# haltium_sysctrl register map
Vendor: Nordic Semiconductor; Series: nRFHaltium; File version: 1
Registers are 32-bit, read-write, reset 0x0 unless marked. A register's access mark holds for its fields unless they carry their own. Offsets are from the block's base; [hi:lo] are bit positions; lines under a group give offsets from that group; {n}, {i} and the like mark numbered series.

## L2CACHEDATA_S — CACHEDATA
Base 0x0E000000
{0x0+0x40*i} SET[{i}] (i=0..255) group — Unspecified
  {0x0+0x20*j} WAY[{j}] (j=0..1) group — Unspecified
    {0x0+8k} DU[{k}] (k=0..3) group — Unspecified
      {0x0+4l} DATA[{l}] (l=0..1) — Description collection: Cache data bits for DATA[q] in DU[p] (DataUnit) of SET[n], WAY[o].
        [31:0] Data

## L2CACHEINFO_S — CACHEINFO
Base 0x0E008000
{0x0+8i} SET[{i}] (i=0..255) group — Unspecified
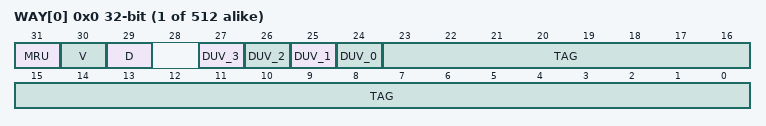
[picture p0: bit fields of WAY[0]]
  {0x0+4j} WAY[{j}] (j=0..1) — Description collection: Cache information for SET[n], WAY[o].
    [31] MRU ro — Most recently used way.
      0=Way0 was most recently used; 1=Way1 was most recently used
    [30] V ro — Line valid bit.
      0=Invalid cache line; 1=Valid cache line
    [29] D ro — Line dirty bit.
      0=Clean cache line; 1=Dirty cache line
    [n+24] DUV_{n} (n=0..3) — Data unit valid info.
      0=Invalid data unit; 1=Valid data unit
    [23:0] TAG — Cache tag.

## GLOBAL_GGENERIC59_NS — GENERIC 0
Base 0xBF001000
Same registers: GLOBAL_GGENERIC55_NS 0x4F8D3000, GLOBAL_GGENERIC56_NS 0x4F8D4000, GLOBAL_GGENERIC57_NS 0x4F8D5000, GLOBAL_GGENERIC58_NS 0x4F8D6000, GGENERIC2_S 0x5F085000, GGENERIC3_S 0x5F096000, GGENERIC6_S 0x5F8CF000, GLOBAL_GGENERIC55_S 0x5F8D3000, GLOBAL_GGENERIC56_S 0x5F8D4000, GLOBAL_GGENERIC57_S 0x5F8D5000, GLOBAL_GGENERIC58_S 0x5F8D6000, GGENERIC7_S 0x5F90E000, GGENERIC8_S 0x5F90F000, GGENERIC9_S 0x5F93C000, GGENERIC12_S 0x5F93F000, GGENERIC13_S 0x5F942000, GGENERIC14_S 0x5F944000, GGENERIC15_S 0x5F945000, GGENERIC16_S 0x5F946000, GGENERIC17_S 0x5F950000, GGENERIC18_S 0x5F952000, GGENERIC19_S 0x5F953000, GGENERIC20_S 0x5F955000, GGENERIC21_S 0x5F956000, GGENERIC22_S 0x5F957000, GGENERIC23_S 0x5F960000, GGENERIC29_S 0x5F967000, GGENERIC30_S 0x5F968000, GGENERIC32_S 0x5F96B000, GGENERIC36_S 0x5F974000, GGENERIC37_S 0x5F975000, GGENERIC38_S 0x5F976000, GGENERIC39_S 0x5F977000, GGENERIC40_S 0x5F978000, GGENERIC41_S 0x5F979000, GGENERIC42_S 0x5F97A000, GGENERIC43_S 0x5F98E000, GGENERIC44_S 0x5F98F000, GGENERIC45_S 0x5F99E000, GGENERIC46_S 0x5F99F000, GGENERIC47_S 0x5F9AE000, GGENERIC48_S 0x5F9AF000, GGENERIC49_S 0x5F9BE000, GGENERIC50_S 0x5F9BF000, GGENERIC51_S 0x5F9CE000, GGENERIC52_S 0x5F9CF000, GGENERIC53_S 0x5F9DE000, GGENERIC54_S 0x5F9DF000, GLOBAL_GGENERIC59_S 0xBF001000 (alternate view of GLOBAL_GGENERIC59_NS), GLOBAL_GGENERIC60_NS 0xBF003000, GLOBAL_GGENERIC60_S 0xBF003000 (alternate view of GLOBAL_GGENERIC60_NS), GLOBAL_TSGEN_NS 0xBF041000, GLOBAL_ETB_NS 0xBF044000, GLOBAL_ETR_NS 0xBF045000
0x00 TASKS_GENERICTASK wo — Generic event
  [0] TASKS_GENERICTASK
    1=Trigger task
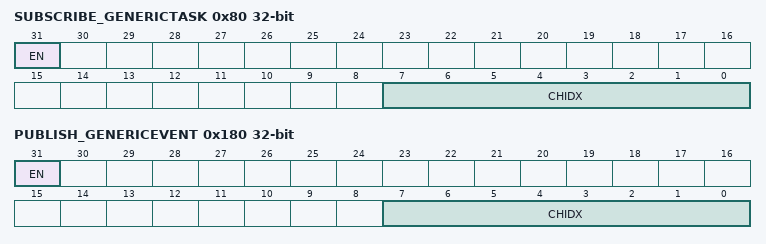
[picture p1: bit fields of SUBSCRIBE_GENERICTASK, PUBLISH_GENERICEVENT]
0x80 SUBSCRIBE_GENERICTASK — Subscribe configuration for task GENERICTASK
  [31] EN
    0=Disabled (Disable subscription); 1=Enabled (Enable subscription)
  [7:0] CHIDX — DPPI channel that task GENERICTASK will subscribe to
0x100 EVENTS_GENERICEVENT — Generic event
  [0] EVENTS_GENERICEVENT
    0=NotGenerated (Event not generated); 1=Generated (Event generated)
0x180 PUBLISH_GENERICEVENT — Publish configuration for event GENERICEVENT
  [31] EN
    0=Disabled (Disable publishing); 1=Enabled (Enable publishing)
  [7:0] CHIDX — DPPI channel that event GENERICEVENT will publish to
0x300 INTEN — Enable or disable interrupt
  [0] GENERICEVENT — Enable or disable interrupt for event GENERICEVENT
    0=Disabled; 1=Enabled
0x304 INTENSET — Enable interrupt
  [0] GENERICEVENT — Write '1' to enable interrupt for event GENERICEVENT
    on read: 0=Disabled (Read: Disabled); 1=Enabled (Read: Enabled) | on write: 1=Set (Enable)
0x308 INTENCLR — Disable interrupt
  [0] GENERICEVENT — Write '1' to disable interrupt for event GENERICEVENT
    on read: 0=Disabled (Read: Disabled); 1=Enabled (Read: Enabled) | on write: 1=Clear (Disable)
